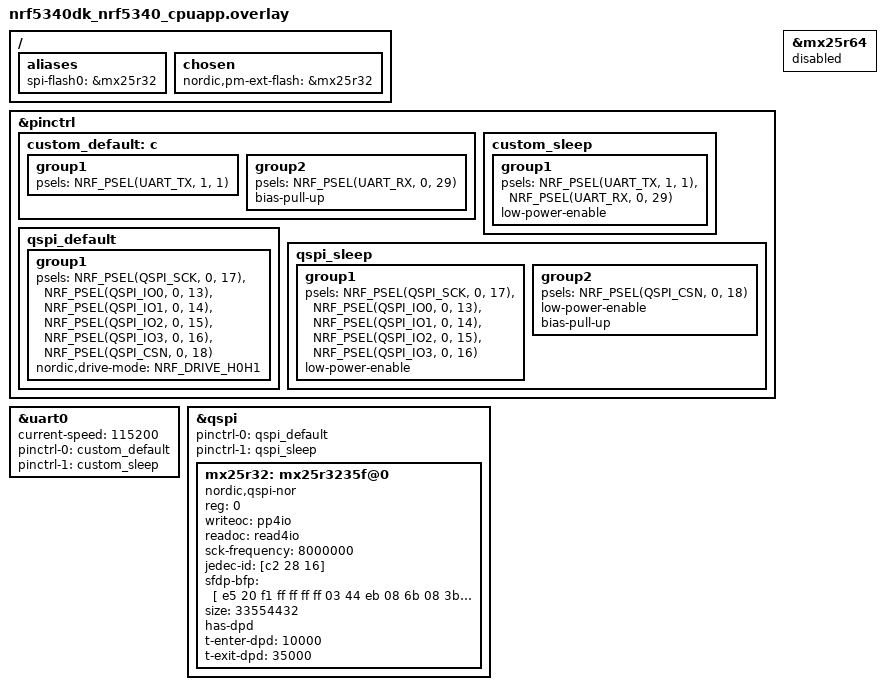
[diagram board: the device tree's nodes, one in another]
/*
 * Copyright (c) 2024, Nestle Purina Pet Care. All rights reserved
 *
 * SPDX-License-Identifier: LicenseRef-BSD-5-Clause-Nordic
 *
 * This is required to get MCUBoot console working on D1
 */

 / {
	aliases {
		spi-flash0 = &mx25r32;
	};
};
&pinctrl {
	custom_default: c {
		group1 {
			psels = <NRF_PSEL(UART_TX, 1, 1)>;
		};
		group2 {
			psels = <NRF_PSEL(UART_RX, 0, 29)>;
			bias-pull-up;
		};
	};
	custom_sleep: custom_sleep {
		group1 {
			psels = <NRF_PSEL(UART_TX, 1, 1)>,
				<NRF_PSEL(UART_RX, 0, 29)>;
			low-power-enable;
		};
	};
	qspi_default: qspi_default {
		group1 {
			psels = <NRF_PSEL(QSPI_SCK, 0, 17)>,
				<NRF_PSEL(QSPI_IO0, 0, 13)>,
				<NRF_PSEL(QSPI_IO1, 0, 14)>,
				<NRF_PSEL(QSPI_IO2, 0, 15)>,
				<NRF_PSEL(QSPI_IO3, 0, 16)>,
				<NRF_PSEL(QSPI_CSN, 0, 18)>;
			nordic,drive-mode = <NRF_DRIVE_H0H1>;
		};
	};
	qspi_sleep: qspi_sleep {
		group1 {
			psels = <NRF_PSEL(QSPI_SCK, 0, 17)>,
				<NRF_PSEL(QSPI_IO0, 0, 13)>,
				<NRF_PSEL(QSPI_IO1, 0, 14)>,
				<NRF_PSEL(QSPI_IO2, 0, 15)>,
				<NRF_PSEL(QSPI_IO3, 0, 16)>;
			low-power-enable;
		};
		group2 {
			psels = <NRF_PSEL(QSPI_CSN, 0, 18)>;
			low-power-enable;
			bias-pull-up;
		};
	};

};

&uart0 {
	status = "okay";
	current-speed = <115200>;
	pinctrl-0 = <&custom_default>;
	pinctrl-1 = <&custom_sleep>;
	pinctrl-names = "default", "sleep";
};

&qspi {
	status = "okay";
	pinctrl-0 = <&qspi_default>;
	pinctrl-1 = <&qspi_sleep>;
	pinctrl-names = "default", "sleep";
	mx25r32: mx25r3235f@0 {
		compatible = "nordic,qspi-nor";
		reg = <0>;
		/* MX25R32 supports only pp and pp4io */
		writeoc = "pp4io";
		/* MX25R32 supports all readoc options */
		readoc = "read4io";
		sck-frequency = <8000000>;
		jedec-id = [c2 28 16];
		sfdp-bfp = [
			e5 20 f1 ff  ff ff ff 03  44 eb 08 6b  08 3b 04 bb
			ee ff ff ff  ff ff 00 ff  ff ff 00 ff  0c 20 0f 52
			10 d8 00 ff  23 72 f5 00  82 ed 04 cc  44 83 68 44
			30 b0 30 b0  f7 c4 d5 5c  00 be 29 ff  f0 d0 ff ff
		];
		size = <33554432>;
		has-dpd;
		t-enter-dpd = <10000>;
		t-exit-dpd = <35000>;
	};
};


&mx25r64 {
	status = "disabled";
};

/ {
	chosen {
			nordic,pm-ext-flash = &mx25r32;
	};
};
